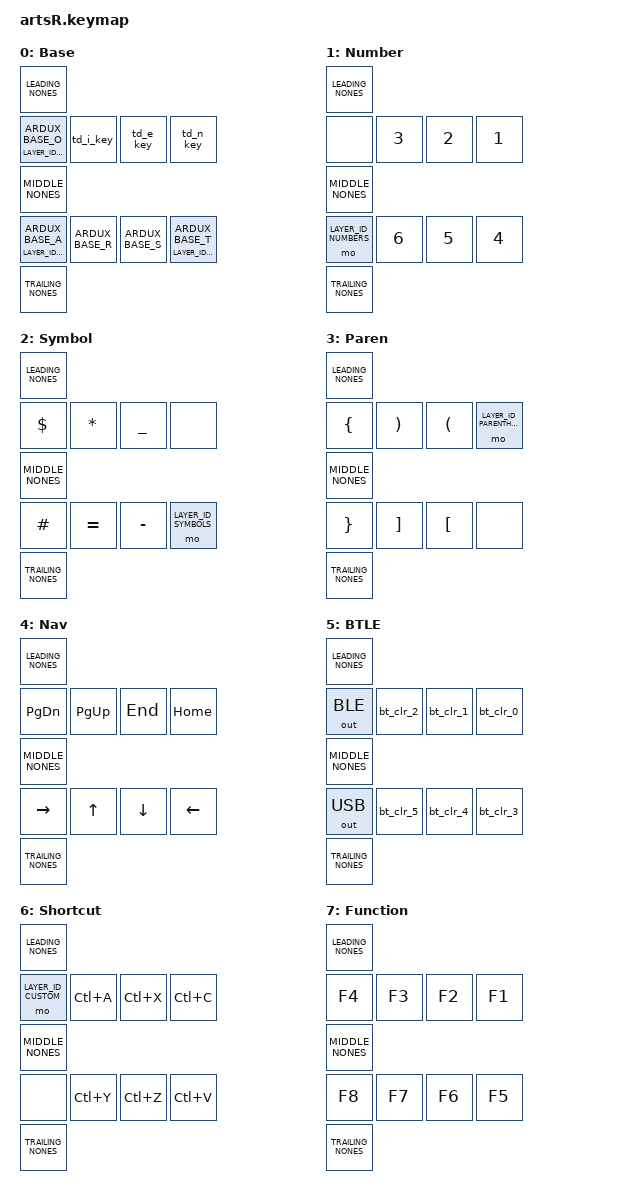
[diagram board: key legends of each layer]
#include <behaviors.dtsi>
#include <dt-bindings/zmk/keys.h>
#include <dt-bindings/zmk/bt.h>
#include <dt-bindings/zmk/outputs.h>

/*****************************************
 * ARDUX website : https://www.ardux.io
 * Primary reference : https://www.ardux.io/_FILES/images/ARDUX.jpg
*****************************************/

/*****************************************
 * Macros for filling in "&none" in the right places in the keymap for re-use needs
 *****************************************/
#define NONE0(X)
#define NONE1(X) X
#define NONE2(X) NONE1(X) X
#define NONE3(X) NONE2(X) X
#define NONE4(X) NONE3(X) X
#define NONE5(X) NONE4(X) X
#define NONE6(X) NONE5(X) X
#define NONE7(X) NONE6(X) X
#define NONE8(X) NONE7(X) X
#define NONE9(X) NONE8(X) X
#define NONE10(X) NONE9(X) X

#define LEADING_NONES NONE(0,0,0)
#define MIDDLE_NONES NONE(0, 0, 0)
#define TRAILING_NONES NONE(0, 0, 0)

#define NONE(HUNDREDS,TENS,ONES) \
  NONE##HUNDREDS(NONE10(NONE10(&none))) \
  NONE##TENS(NONE10(&none)) \
  NONE##ONES(&none)

/*****************************************
 * Define key positions used for combos
 * These definitions are used to define the various ARDUX combos
 * 
 * Please see the documentation on "combos" for details on how to find the proper key positions
 *
 * Default key positions are for a generic 4x2 keyboard and should NOT be used outright
 * DEFINE these definitions in your boards keymap BEFORE including ardux.dtsi
*****************************************/
 // NEIO Row
 #define KEY_O 0
 #define KEY_I 1
 #define KEY_E 2
 #define KEY_N 3
// ARST Row
 #define KEY_A 4
 #define KEY_R 5
 #define KEY_S 6
 #define KEY_T 7

//N E I O
//0 1 2 3

//T S R A
//4 5 6 7

 
/*****************************************
 * Define custom BT layer extra keys
 *
 * You can override the 2 blank keys on the BT select layer by copy/pasting the below into your keymap
 *     *before* including the ardux.dtsfile
 * Once added to your keymap you can adjust these 2 keys as you see fit
*****************************************/
#if !defined ARDUX_BT_TOP
#define ARDUX_BT_TOP &out OUT_BLE
#endif
#if !defined ARDUX_BT_BOTTOM
#define ARDUX_BT_BOTTOM &out OUT_USB
#endif

/*****************************************
 * Define how long it takes for the combos/holds to 'time out'
 * See documentation on "combos" for more detail
 * THE COMBO TIMEOUTS MUST BE THE SAME
 *    https://github.com/zmkfirmware/zmk/issues/905
 *****************************************/
#if !defined TIMEOUT_COMBO_2
#define TIMEOUT_COMBO_2 175
#endif
#if !defined TIMEOUT_COMBO_3
#define TIMEOUT_COMBO_3 175
#endif
#if !defined TIMEOUT_COMBO_4
#define TIMEOUT_COMBO_4 175
#endif
#if !defined TIMEOUT_LAYER_HOLD
#define TIMEOUT_LAYER_HOLD 200
#endif
#if !defined TIMEOUT_STICKY_LEADER_KEY
#define TIMEOUT_STICKY_LEADER_KEY 5000
#endif
&sk {
	release-after-ms = <TIMEOUT_STICKY_LEADER_KEY>;
};
&sl { 
	release-after-ms = <TIMEOUT_STICKY_LEADER_KEY>;
};


/*****************************************
 * Define base layer chars for 'standard ARDUX' or 'COLEMAK' inspired (you can add more by following the pattern below)
 * Turn on the ARDUX_COLEMAK definition above if you want this change
 *****************************************/
#define ARDUX_BASE_N N
#define ARDUX_BASE_E E
#define ARDUX_BASE_I I
#define ARDUX_BASE_O O
#define ARDUX_BASE_A A
#define ARDUX_BASE_S S
#define ARDUX_BASE_R R
#define ARDUX_BASE_T T


/*****************************************
 * Layer IDs used by the ARDUX keymap
 * Do NOT change these and do NOT change the order of the layers as shown below
 *****************************************/
#define LAYER_ID_GLOBAL -1
#define LAYER_ID_BASE 0
#define LAYER_ID_NUMBERS 1
#define LAYER_ID_SYMBOLS 2
#define LAYER_ID_PARENTHETICALS 3
#define LAYER_ID_NAVIGATION 4
#define LAYER_ID_BT_SEL 5
#define LAYER_ID_CUSTOM 6
#define LAYER_ID_FUNCTIONS 7

/*****************************************
 * Standard ARDUX combo definitions
 * These should NOT be changed and are global in scope
 *****************************************/
/ {
	combos {
		compatible = "zmk,combos";
		/*****************************************
		 * 2 key combos
		 *****************************************/
		combo_enter      { layers = <LAYER_ID_BASE>; timeout-ms = <TIMEOUT_COMBO_2>; key-positions = <KEY_N KEY_T>; bindings = <&kp ENTER>; };
		combo_gui        { layers = <LAYER_ID_BASE>; timeout-ms = <TIMEOUT_COMBO_2>; key-positions = <KEY_S KEY_O>; bindings = <&kp LGUI>; };
		
		combo_backspace  { layers = <LAYER_ID_BASE>; timeout-ms = <TIMEOUT_COMBO_2>; key-positions = <KEY_T KEY_E>; bindings = <&kp BACKSPACE>; };
		combo_delete     { layers = <LAYER_ID_BASE>; timeout-ms = <TIMEOUT_COMBO_2>; key-positions = <KEY_E KEY_R>; bindings = <&kp DELETE>; };
		combo_shift      { layers = <LAYER_ID_BASE>; timeout-ms = <TIMEOUT_COMBO_2>; key-positions = <KEY_N KEY_S>; bindings = <&sk LSHFT>; };

		combo_tab        { layers = <LAYER_ID_BASE>; timeout-ms = <TIMEOUT_COMBO_2>; key-positions = <KEY_T KEY_I>; bindings = <&kp TAB>; };	
		combo_space      { layers = <LAYER_ID_BASE>; timeout-ms = <TIMEOUT_COMBO_2>; key-positions = <KEY_T KEY_S>; bindings = <&kp SPACE>; };	
		
		//combo_ptab       { layers = <LAYER_ID_MOUSE>; timeout-ms = <TIMEOUT_COMBO_2>; key-positions = <KEY_Y KEY_I>; bindings = <&kp LG(LBRC)>; };
		//combo_ntab       { layers = <LAYER_ID_MOUSE>; timeout-ms = <TIMEOUT_COMBO_2>; key-positions = <KEY_E KEY_Y>; bindings = <&kp RG(RBRC)>; };
		//combo_bck        { layers = <LAYER_ID_MOUSE>; timeout-ms = <TIMEOUT_COMBO_2>; key-positions = <KEY_A KEY_Y>; bindings = <&kp LG(LBKT)>; };
		//combo_fwd        { layers = <LAYER_ID_MOUSE>; timeout-ms = <TIMEOUT_COMBO_2>; key-positions = <KEY_R KEY_R>; bindings = <&kp RG(RBKT)>; };

		combo_b           { layers = <LAYER_ID_BASE>; timeout-ms = <TIMEOUT_COMBO_2>; key-positions = <KEY_T KEY_A>; bindings = <&kp B>; };
		combo_c           { layers = <LAYER_ID_BASE>; timeout-ms = <TIMEOUT_COMBO_2>; key-positions = <KEY_R KEY_A>; bindings = <&kp C>; };
		combo_f           { layers = <LAYER_ID_BASE>; timeout-ms = <TIMEOUT_COMBO_2>; key-positions = <KEY_N KEY_E>; bindings = <&kp F>; };
		combo_g           { layers = <LAYER_ID_BASE>; timeout-ms = <TIMEOUT_COMBO_2>; key-positions = <KEY_E KEY_I>; bindings = <&kp G>; };
		combo_u           { layers = <LAYER_ID_BASE>; timeout-ms = <TIMEOUT_COMBO_2>; key-positions = <KEY_S KEY_R>; bindings = <&kp U>; };
		combo_h           { layers = <LAYER_ID_BASE>; timeout-ms = <TIMEOUT_COMBO_2>; key-positions = <KEY_T KEY_R>; bindings = <&kp H>; };
		combo_v           { layers = <LAYER_ID_BASE>; timeout-ms = <TIMEOUT_COMBO_2>; key-positions = <KEY_E KEY_O>; bindings = <&kp V>; };
		combo_j           { layers = <LAYER_ID_BASE>; timeout-ms = <TIMEOUT_COMBO_2>; key-positions = <KEY_I KEY_O>; bindings = <&kp J>; };
		combo_w           { layers = <LAYER_ID_BASE>; timeout-ms = <TIMEOUT_COMBO_2>; key-positions = <KEY_N KEY_O>; bindings = <&kp W>; };
		combo_k           { layers = <LAYER_ID_BASE>; timeout-ms = <TIMEOUT_COMBO_2>; key-positions = <KEY_S KEY_A>; bindings = <&kp K>; };
		combo_y           { layers = <LAYER_ID_BASE>; timeout-ms = <TIMEOUT_COMBO_2>; key-positions = <KEY_N KEY_I>; bindings = <&kp Y>; };
		combo_period      { layers = <LAYER_ID_BASE>; timeout-ms = <TIMEOUT_COMBO_2>; key-positions = <KEY_I KEY_R>; bindings = <&kp PERIOD>; };
		combo_comma       { layers = <LAYER_ID_BASE>; timeout-ms = <TIMEOUT_COMBO_2>; key-positions = <KEY_E KEY_S>; bindings = <&kp COMMA>; };
		combo_b_backslash { layers = <LAYER_ID_BASE>; timeout-ms = <TIMEOUT_COMBO_2>; key-positions = <KEY_N KEY_A>; bindings = <&kp BACKSLASH>; };
		combo_slash       { layers = <LAYER_ID_BASE>; timeout-ms = <TIMEOUT_COMBO_2>; key-positions = <KEY_T KEY_O>; bindings = <&kp SLASH>; };
		combo_exclamation { layers = <LAYER_ID_BASE>; timeout-ms = <TIMEOUT_COMBO_2>; key-positions = <KEY_N KEY_R>; bindings = <&kp EXCL>; };
		combo_colon       { layers = <LAYER_ID_BASE>; timeout-ms = <TIMEOUT_COMBO_2>; key-positions = <KEY_E KEY_A>; bindings = <&kp COLON>; };	
		combo_semi_colon  { layers = <LAYER_ID_BASE>; timeout-ms = <TIMEOUT_COMBO_2>; key-positions = <KEY_A KEY_I>; bindings = <&kp SEMI>; };		
		combo_alt_tab     { layers = <LAYER_ID_BASE>; timeout-ms = <TIMEOUT_COMBO_2>; key-positions = <KEY_O KEY_A>; bindings = <&kp LA(TAB)>; };

		combo_seven { layers = <LAYER_ID_NUMBERS>; timeout-ms = <TIMEOUT_COMBO_2>; key-positions = <KEY_T KEY_S>; bindings = <&kp N7>; };
		combo_eight { layers = <LAYER_ID_NUMBERS>; timeout-ms = <TIMEOUT_COMBO_2>; key-positions = <KEY_S KEY_R>; bindings = <&kp N8>; };
		combo_nine  { layers = <LAYER_ID_NUMBERS>; timeout-ms = <TIMEOUT_COMBO_2>; key-positions = <KEY_E KEY_I>; bindings = <&kp N9>; };
		combo_zero  { layers = <LAYER_ID_NUMBERS>; timeout-ms = <TIMEOUT_COMBO_2>; key-positions = <KEY_N KEY_E>; bindings = <&kp N0>; };

		combo_lt     { layers = <LAYER_ID_PARENTHETICALS>; timeout-ms = <TIMEOUT_COMBO_2>; key-positions = <KEY_E KEY_I>; bindings = <&kp LT>; };
		combo_gt     { layers = <LAYER_ID_PARENTHETICALS>; timeout-ms = <TIMEOUT_COMBO_2>; key-positions = <KEY_I KEY_O>; bindings = <&kp GT>; };
		combo_tilde  { layers = <LAYER_ID_PARENTHETICALS>; timeout-ms = <TIMEOUT_COMBO_2>; key-positions = <KEY_S KEY_R>; bindings = <&kp TILDE>; };
		combo_caret  { layers = <LAYER_ID_PARENTHETICALS>; timeout-ms = <TIMEOUT_COMBO_2>; key-positions = <KEY_R KEY_A>; bindings = <&kp CARET>; };
		
		combo_at        { layers = <LAYER_ID_SYMBOLS>; timeout-ms = <TIMEOUT_COMBO_2>; key-positions = <KEY_I KEY_O>; bindings = <&kp AT>; };
		combo_backslash { layers = <LAYER_ID_SYMBOLS>; timeout-ms = <TIMEOUT_COMBO_2>; key-positions = <KEY_E KEY_I>; bindings = <&kp BACKSLASH>; };
		combo_pipe      { layers = <LAYER_ID_SYMBOLS>; timeout-ms = <TIMEOUT_COMBO_2>; key-positions = <KEY_R KEY_A>; bindings = <&kp PIPE>; };
		combo_ampersand { layers = <LAYER_ID_SYMBOLS>; timeout-ms = <TIMEOUT_COMBO_2>; key-positions = <KEY_S KEY_R>; bindings = <&kp AMPERSAND>; };
		combo_percent   { layers = <LAYER_ID_SYMBOLS>; timeout-ms = <TIMEOUT_COMBO_2>; key-positions = <KEY_N KEY_T>; bindings = <&kp PERCENT>; };
		combo_plus      { layers = <LAYER_ID_SYMBOLS>; timeout-ms = <TIMEOUT_COMBO_2>; key-positions = <KEY_E KEY_S>; bindings = <&kp PLUS>; };	
		combo_grave     { layers = <LAYER_ID_SYMBOLS>; timeout-ms = <TIMEOUT_COMBO_2>; key-positions = <KEY_I KEY_R>; bindings = <&kp GRAVE>; };

		combo_ctrl_save { layers = <LAYER_ID_CUSTOM>; timeout-ms = <TIMEOUT_COMBO_2>; key-positions = <KEY_E KEY_I>; bindings = <&kp LC(S)>; };
		combo_ctrl_find { layers = <LAYER_ID_CUSTOM>; timeout-ms = <TIMEOUT_COMBO_2>; key-positions = <KEY_N KEY_E>; bindings = <&kp LC(F)>; };

		combo_F9 { layers = <LAYER_ID_FUNCTIONS>; timeout-ms = <TIMEOUT_COMBO_2>; key-positions = <KEY_N KEY_E>; bindings = <&kp F9>; };
		combo_F10 { layers = <LAYER_ID_FUNCTIONS>; timeout-ms = <TIMEOUT_COMBO_2>; key-positions = <KEY_I KEY_O>; bindings = <&kp F10>; };
		combo_F11 { layers = <LAYER_ID_FUNCTIONS>; timeout-ms = <TIMEOUT_COMBO_2>; key-positions = <KEY_T KEY_S>; bindings = <&kp F11>; };
		combo_F12 { layers = <LAYER_ID_FUNCTIONS>; timeout-ms = <TIMEOUT_COMBO_2>; key-positions = <KEY_R KEY_A>; bindings = <&kp F12>; };

		combo_nav_ctrl  { layers = <LAYER_ID_NAVIGATION>; timeout-ms = <TIMEOUT_COMBO_2>; key-positions = <KEY_N KEY_E>; bindings = <&kt LCTRL>; };
		combo_nav_shift { layers = <LAYER_ID_NAVIGATION>; timeout-ms = <TIMEOUT_COMBO_2>; key-positions = <KEY_I KEY_O>; bindings = <&kt LSHIFT>; };
		
		/*****************************************
		 * 3 key combos
		 *****************************************/
		 
		combo_esc              { timeout-ms = <TIMEOUT_COMBO_3>; key-positions = <KEY_N KEY_E KEY_A>; bindings = <&kp ESC>; };
		combo_layer_navigation { timeout-ms = <TIMEOUT_COMBO_3>; key-positions = <KEY_T KEY_E KEY_R>; bindings = <&tog LAYER_ID_NAVIGATION>; };
		//combo_layer_mouse    { timeout-ms = <TIMEOUT_COMBO_3>; key-positions = <KEY_A KEY_T KEY_Y>; bindings = <&tog LAYER_ID_MOUSE>; };

		combo_m            { layers = <LAYER_ID_BASE>; timeout-ms = <TIMEOUT_COMBO_3>; key-positions = <KEY_S KEY_R KEY_A>; bindings = <&kp M>; };
		combo_d            { layers = <LAYER_ID_BASE>; timeout-ms = <TIMEOUT_COMBO_3>; key-positions = <KEY_N KEY_E KEY_I>; bindings = <&kp D>; };
		combo_p            { layers = <LAYER_ID_BASE>; timeout-ms = <TIMEOUT_COMBO_3>; key-positions = <KEY_T KEY_E KEY_I>; bindings = <&kp P>; };
		combo_q            { layers = <LAYER_ID_BASE>; timeout-ms = <TIMEOUT_COMBO_3>; key-positions = <KEY_E KEY_R KEY_A>; bindings = <&kp Q>; };
		combo_l            { layers = <LAYER_ID_BASE>; timeout-ms = <TIMEOUT_COMBO_3>; key-positions = <KEY_T KEY_S KEY_R>; bindings = <&kp L>; };	
		combo_x            { layers = <LAYER_ID_BASE>; timeout-ms = <TIMEOUT_COMBO_3>; key-positions = <KEY_E KEY_I KEY_O>; bindings = <&kp X>; };
		combo_single_quote { layers = <LAYER_ID_BASE>; timeout-ms = <TIMEOUT_COMBO_3>; key-positions = <KEY_N KEY_S KEY_R>; bindings = <&kp SQT>; };
		combo_double_quote { layers = <LAYER_ID_BASE>; timeout-ms = <TIMEOUT_COMBO_3>; key-positions = <KEY_N KEY_R KEY_A>; bindings = <&kp DQT>; };
		combo_qmark        { layers = <LAYER_ID_BASE>; timeout-ms = <TIMEOUT_COMBO_3>; key-positions = <KEY_N KEY_I KEY_A>; bindings = <&kp QMARK>; };
		combo_bt_ldr       { layers = <LAYER_ID_BASE>; timeout-ms = <TIMEOUT_COMBO_3>; key-positions = <KEY_T KEY_I KEY_O>; bindings = <&bootloader>; };
		combo_ctrl         { layers = <LAYER_ID_BASE>; timeout-ms = <TIMEOUT_COMBO_3>; key-positions = <KEY_N KEY_E KEY_O>; bindings = <&sk LCTRL>; };
		combo_caps_lock    { layers = <LAYER_ID_BASE>; timeout-ms = <TIMEOUT_COMBO_3>; key-positions = <KEY_T KEY_S KEY_A>; bindings = <&kp CAPS>; };
		combo_arrow_r      { layers = <LAYER_ID_BASE>; timeout-ms = <TIMEOUT_COMBO_3>; key-positions = <KEY_E KEY_S KEY_R>; bindings = <&kp RIGHT>; };
		combo_arrow_l      { layers = <LAYER_ID_BASE>; timeout-ms = <TIMEOUT_COMBO_3>; key-positions = <KEY_T KEY_E KEY_S>; bindings = <&kp LEFT>; };

		combo_num_period  { layers = <LAYER_ID_NUMBERS>; timeout-ms = <TIMEOUT_COMBO_3>; key-positions = <KEY_N KEY_E KEY_I>; bindings = <&kp PERIOD>; };
		combo_num_comma   { layers = <LAYER_ID_NUMBERS>; timeout-ms = <TIMEOUT_COMBO_3>; key-positions = <KEY_T KEY_S KEY_R>; bindings = <&kp COMMA>; };


		combo_bt_clr     { layers = <LAYER_ID_BT_SEL>; timeout-ms = <TIMEOUT_COMBO_3>; key-positions = <KEY_N KEY_E KEY_I>; bindings = <&bt BT_CLR>; };
		//combo_bt_clr_all { layers = <LAYER_ID_BT_SEL>; timeout-ms = <TIMEOUT_COMBO_3>; key-positions = <KEY_R KEY_T KEY_S>; bindings = <&bt BT_CLR_ALL>; };

		combo_print_scrn  { layers = <LAYER_ID_CUSTOM>; timeout-ms = <TIMEOUT_COMBO_3>; key-positions = <KEY_N KEY_E KEY_I>; bindings = <&kp PSCRN>; };
		
		/*****************************************
		 * 4 key combos
		 *****************************************/
		combo_layer_bt_select { timeout-ms = <TIMEOUT_COMBO_4>; key-positions = <KEY_N KEY_T KEY_O KEY_A>; bindings = <&tog LAYER_ID_BT_SEL>; };

		combo_z         { layers = <LAYER_ID_BASE>; timeout-ms = <TIMEOUT_COMBO_4>; key-positions = <KEY_N KEY_E KEY_I KEY_O>; bindings = <&kp Z>; };
		combo_arrow_d         { layers = <LAYER_ID_BASE>; timeout-ms = <TIMEOUT_COMBO_4>; key-positions = <KEY_T KEY_E KEY_I KEY_O>; bindings = <&kp DOWN>; };
		combo_arrow_u         { layers = <LAYER_ID_BASE>; timeout-ms = <TIMEOUT_COMBO_4>; key-positions = <KEY_N KEY_S KEY_R KEY_A>; bindings = <&kp UP>; };

		combo_layer_functions { timeout-ms = <TIMEOUT_COMBO_4>; key-positions = <KEY_N KEY_T KEY_E KEY_S>; bindings = <&tog LAYER_ID_FUNCTIONS>; };
	};
};

/*****************************************
 * Personal Macros
 *****************************************/
/ {
    macros {
        numlock: numlock {
            compatible = "zmk,behavior-macro";
            #binding-cells = <0>;
            bindings
                = <&macro_tap &kp KP_NUM>
                , <&macro_pause_for_release>
                , <&macro_tap &kp KP_NUM>
                ;
        };
		bt_clr_0: bt_clr_0 {
            compatible = "zmk,behavior-macro";
            #binding-cells = <0>;
            bindings = <&bt BT_SEL 0 &out OUT_BLE>;
        };
		bt_clr_1: bt_clr_1 {
            compatible = "zmk,behavior-macro";
            #binding-cells = <0>;
            bindings = <&bt BT_SEL 1 &out OUT_BLE>;
        };	
		bt_clr_2: bt_clr_2 {
            compatible = "zmk,behavior-macro";
            #binding-cells = <0>;
            bindings = <&bt BT_SEL 2 &out OUT_BLE>;
        };
		bt_clr_3: bt_clr_3 {
            compatible = "zmk,behavior-macro";
            #binding-cells = <0>;
            bindings = <&bt BT_SEL 3 &out OUT_BLE>;
        };
		bt_clr_4: bt_clr_4 {
            compatible = "zmk,behavior-macro";
            #binding-cells = <0>;
            bindings = <&bt BT_SEL 4 &out OUT_BLE>;
        };
		bt_clr_5: bt_clr_5 {
            compatible = "zmk,behavior-macro";
            #binding-cells = <0>;
            bindings = <&bt BT_SEL 5 &out OUT_BLE>;
        };
    };
}; 

/*****************************************
 * Standard ARDUX layer activation definitions
 * These should NOT be changed and are global in scope
 *****************************************/
/ {
	behaviors {
		layer_base_kp: layer_base_kp { compatible = "zmk,behavior-hold-tap";
						#binding-cells = <2>; tapping-term-ms = <TIMEOUT_LAYER_HOLD>; flavor = "tap-preferred"; 
						bindings = <&mo>, <&kp>; };
		layer_numbers_kp: layer_numbers_kp { compatible = "zmk,behavior-hold-tap";
						#binding-cells = <2>; tapping-term-ms = <TIMEOUT_LAYER_HOLD>; flavor = "tap-preferred"; 
						bindings = <&mo>, <&kp>; };
		layer_symbols_kp: layer_symbols_kp { compatible = "zmk,behavior-hold-tap";
						#binding-cells = <2>; tapping-term-ms = <TIMEOUT_LAYER_HOLD>; flavor = "tap-preferred"; 
						bindings = <&mo>, <&kp>; };
		layer_parentheticals_kp: layer_parentheticals_kp { compatible = "zmk,behavior-hold-tap";
						#binding-cells = <2>; tapping-term-ms = <TIMEOUT_LAYER_HOLD>; flavor = "tap-preferred";
						bindings = <&mo>, <&kp>; };
		layer_custom_kp: layer_custom_kp { compatible = "zmk,behavior-hold-tap";
						#binding-cells = <2>; tapping-term-ms = <TIMEOUT_LAYER_HOLD>; flavor = "tap-preferred";
						bindings = <&mo>, <&kp>; };
		layer_functions_kp: layer_functions_kp { compatible = "zmk,behavior-hold-tap";
						#binding-cells = <2>; tapping-term-ms = <TIMEOUT_LAYER_HOLD>; flavor = "tap-preferred";
						bindings = <&mo>, <&kp>; };
		ctrl_alt_kp: ctrl_alt_kp { compatible = "zmk,behavior-hold-tap";
						#binding-cells = <2>; tapping-term-ms = <TIMEOUT_LAYER_HOLD>; flavor = "tap-preferred";
						bindings = <&sk>, <&sk>; };
		td_n_key: td_n_key {
            compatible = "zmk,behavior-tap-dance";
            #binding-cells = <0>;
            tapping-term-ms = <250>;
            bindings = <&layer_parentheticals_kp LAYER_ID_PARENTHETICALS ARDUX_BASE_N>, <&kt LCTRL>;
        };
		td_e_key: td_e_key {
            compatible = "zmk,behavior-tap-dance";
            #binding-cells = <0>;
            tapping-term-ms = <250>;
            bindings = <&kp ARDUX_BASE_E>, <&kt LSHIFT>;
        };
		td_i_key: td_i_key {
            compatible = "zmk,behavior-tap-dance";
            #binding-cells = <0>;
            tapping-term-ms = <250>;
            bindings = <&kp ARDUX_BASE_I>, <&kt LC(LSHIFT)>;
        };
	};
};

/*****************************************
 * Standard ARDUX layer definitions
 * !!!!!!!!!! FOR LEFT HANDED USE !!!!!!!!!!
 *****************************************/
/ {
	keymap {
		compatible = "zmk,keymap";
		base {
			display-name = "Base";
			bindings = <
				LEADING_NONES
				&layer_custom_kp LAYER_ID_CUSTOM   ARDUX_BASE_O        &td_i_key     &td_e_key     &td_n_key
				MIDDLE_NONES
				&layer_numbers_kp LAYER_ID_NUMBERS ARDUX_BASE_A          &kp ARDUX_BASE_R     &kp ARDUX_BASE_S    &layer_symbols_kp LAYER_ID_SYMBOLS ARDUX_BASE_T
				TRAILING_NONES
			>;
		};
		numbers {
			display-name = "Number";
			bindings = <
				LEADING_NONES
				&none &kp N3    &kp N2    &kp N1 
				MIDDLE_NONES
				&mo LAYER_ID_NUMBERS &kp N6    &kp N5    &kp N4  
				TRAILING_NONES
			>;
		};
		symbols {
			display-name = "Symbol";
			bindings = <
				LEADING_NONES
				&kp DOLLAR  &kp ASTERISK  &kp  UNDERSCORE &none
				MIDDLE_NONES
				&kp   HASH  &kp EQUAL &kp  MINUS  &mo LAYER_ID_SYMBOLS
				TRAILING_NONES
			>;
		};
		parentheticals {
			display-name = "Paren";
			bindings = <
				LEADING_NONES
				&kp  LBRC   &kp RPAR  &kp   LPAR &mo LAYER_ID_PARENTHETICALS
				MIDDLE_NONES
				&kp RBRC    &kp RBKT  &kp LBKT  &none
				TRAILING_NONES
			>;
		};
		navigation {
			display-name = "Nav";
			bindings = <
				LEADING_NONES
				 &kp PG_DN  &kp  PG_UP  &kp END &kp HOME
				MIDDLE_NONES
				&kp RIGHT   &kp UP  &kp DOWN &kp LEFT
				TRAILING_NONES
			>;
		};
		/*bt {
			label = "BTLE";
			bindings = <
				LEADING_NONES
				ARDUX_BT_TOP    &bt BT_SEL 3 &bt BT_SEL 4 &bt BT_SEL 5
				MIDDLE_NONES
				ARDUX_BT_BOTTOM &bt BT_SEL 0 &bt BT_SEL 1 &bt BT_SEL 2
				TRAILING_NONES
			>;
		};*/
		bt {
			display-name = "BTLE";
			bindings = <
				LEADING_NONES
				ARDUX_BT_TOP &bt_clr_2 &bt_clr_1 &bt_clr_0 
				MIDDLE_NONES
				ARDUX_BT_BOTTOM &bt_clr_5 &bt_clr_4 &bt_clr_3 
				TRAILING_NONES
			>;
		};
		custom {                                                              
			display-name = "Shortcut";                                                 
			bindings = <                                                      
				LEADING_NONES                                                 
				&mo LAYER_ID_CUSTOM  &kp LC(A)  &kp LC(X)   &kp LC(C)
				MIDDLE_NONES
				&none   &kp LC(Y)  &kp LC(Z)   &kp LC(V)
				TRAILING_NONES
			>;
		};
		functions {
			display-name = "Function";
			bindings = <
				LEADING_NONES
				&kp F4        &kp F3     &kp F2     &kp F1
				MIDDLE_NONES
				&kp F8          &kp F7     &kp F6     &kp F5
				TRAILING_NONES
			>;
		};
	};
};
